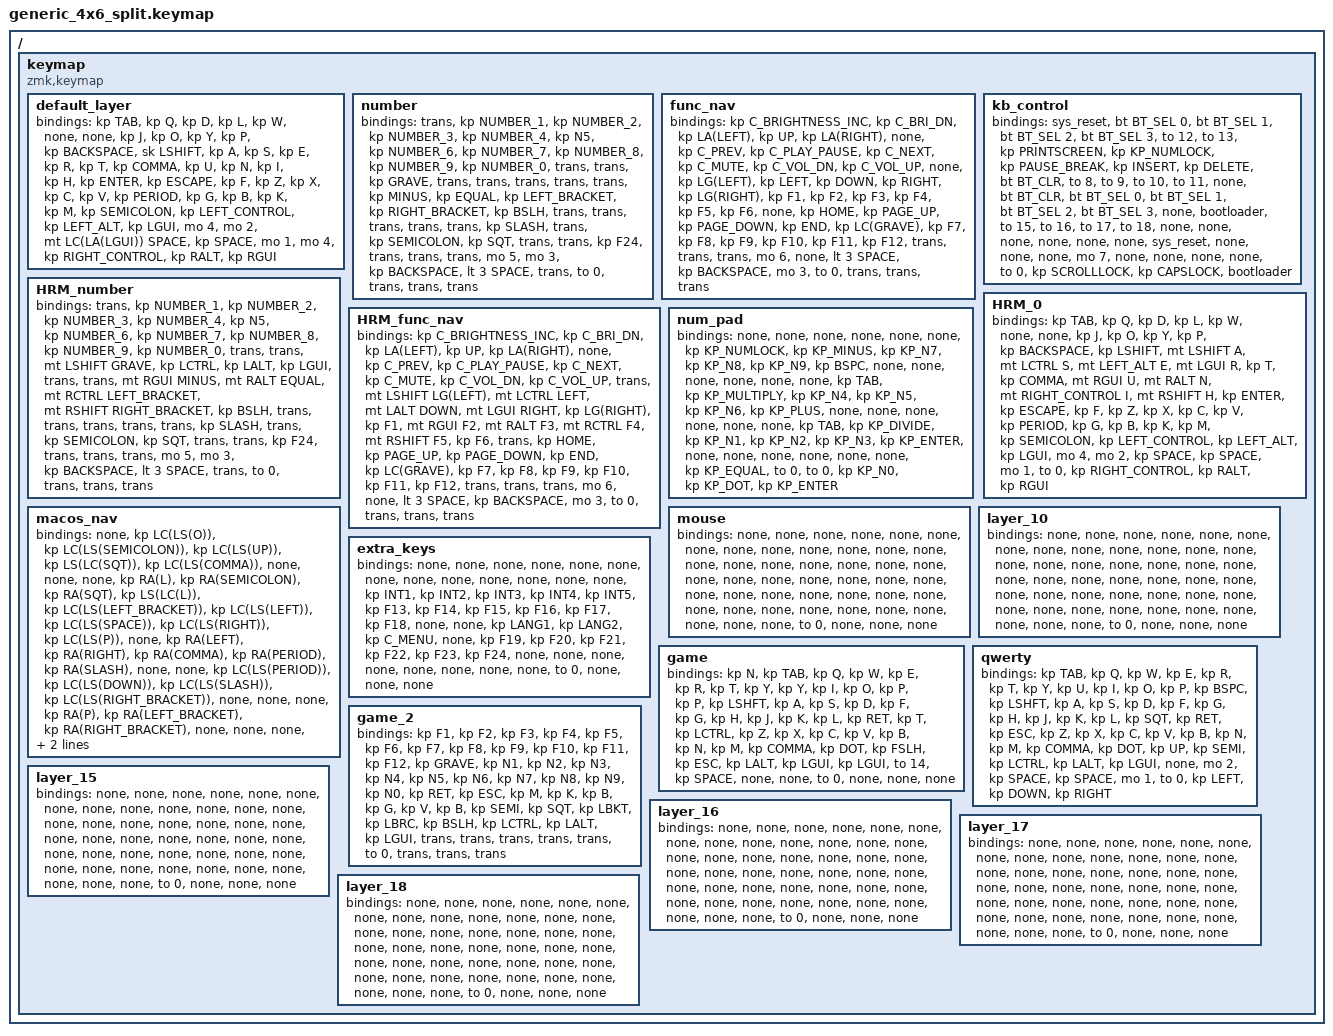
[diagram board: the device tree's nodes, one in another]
#include <behaviors.dtsi>
#include <dt-bindings/zmk/bt.h>
#include <dt-bindings/zmk/keys.h>

/ {
    keymap {
        compatible = "zmk,keymap";

        default_layer {
            bindings = <
&kp TAB  &kp Q  &kp D  &kp L  &kp W  &none  &none  &kp J  &kp O  &kp Y  &kp P  &kp BACKSPACE  &sk LSHIFT  &kp A  &kp S  &kp E  &kp R  &kp T  &kp COMMA  &kp U  &kp N  &kp I  &kp H  &kp ENTER  &kp ESCAPE  &kp F  &kp Z  &kp X  &kp C  &kp V  &kp PERIOD  &kp G  &kp B  &kp K  &kp M  &kp SEMICOLON  &kp LEFT_CONTROL  &kp LEFT_ALT  &kp LGUI  &mo 4  &mo 2  &mt LC(LA(LGUI)) SPACE  &kp SPACE  &mo 1  &mo 4  &kp RIGHT_CONTROL  &kp RALT  &kp RGUI
            >;
        };

        number {
            bindings = <
&trans  &kp NUMBER_1  &kp NUMBER_2  &kp NUMBER_3  &kp NUMBER_4  &kp N5  &kp NUMBER_6  &kp NUMBER_7  &kp NUMBER_8  &kp NUMBER_9  &kp NUMBER_0  &trans  &trans  &kp GRAVE  &trans  &trans  &trans  &trans  &trans  &kp MINUS  &kp EQUAL  &kp LEFT_BRACKET  &kp RIGHT_BRACKET  &kp BSLH  &trans  &trans  &trans  &trans  &trans  &kp SLASH  &trans  &kp SEMICOLON  &kp SQT  &trans  &trans  &kp F24  &trans  &trans  &trans  &mo 5  &mo 3  &kp BACKSPACE  &lt 3 SPACE  &trans  &to 0  &trans  &trans  &trans
            >;
        };

        func_nav {
            bindings = <
&kp C_BRIGHTNESS_INC  &kp C_BRI_DN  &kp LA(LEFT)  &kp UP  &kp LA(RIGHT)  &none  &kp C_PREV  &kp C_PLAY_PAUSE  &kp C_NEXT  &kp C_MUTE  &kp C_VOL_DN  &kp C_VOL_UP  &none  &kp LG(LEFT)  &kp LEFT  &kp DOWN  &kp RIGHT  &kp LG(RIGHT)  &kp F1  &kp F2  &kp F3  &kp F4  &kp F5  &kp F6  &none  &kp HOME  &kp PAGE_UP  &kp PAGE_DOWN  &kp END  &kp LC(GRAVE)  &kp F7  &kp F8  &kp F9  &kp F10  &kp F11  &kp F12  &trans  &trans  &trans  &mo 6  &none  &lt 3 SPACE  &kp BACKSPACE  &mo 3  &to 0  &trans  &trans  &trans
            >;
        };

        kb_control {
            bindings = <
&sys_reset  &bt BT_SEL 0  &bt BT_SEL 1  &bt BT_SEL 2  &bt BT_SEL 3  &to 12  &to 13  &kp PRINTSCREEN  &kp KP_NUMLOCK  &kp PAUSE_BREAK  &kp INSERT  &kp DELETE  &bt BT_CLR  &to 8  &to 9  &to 10  &to 11  &none  &bt BT_CLR  &bt BT_SEL 0  &bt BT_SEL 1  &bt BT_SEL 2  &bt BT_SEL 3  &none  &bootloader  &to 15  &to 16  &to 17  &to 18  &none  &none  &none  &none  &none  &none  &sys_reset  &none  &none  &none  &mo 7  &none  &none  &none  &none  &to 0  &kp SCROLLLOCK  &kp CAPSLOCK  &bootloader
            >;
        };

        HRM_0 {
            bindings = <
&kp TAB  &kp Q  &kp D  &kp L  &kp W  &none  &none  &kp J  &kp O  &kp Y  &kp P  &kp BACKSPACE  &kp LSHIFT  &mt LSHIFT A  &mt LCTRL S  &mt LEFT_ALT E  &mt LGUI R  &kp T  &kp COMMA  &mt RGUI U  &mt RALT N  &mt RIGHT_CONTROL I  &mt RSHIFT H  &kp ENTER  &kp ESCAPE  &kp F  &kp Z  &kp X  &kp C  &kp V  &kp PERIOD  &kp G  &kp B  &kp K  &kp M  &kp SEMICOLON  &kp LEFT_CONTROL  &kp LEFT_ALT  &kp LGUI  &mo 4  &mo 2  &kp SPACE  &kp SPACE  &mo 1  &to 0  &kp RIGHT_CONTROL  &kp RALT  &kp RGUI
            >;
        };

        HRM_number {
            bindings = <
&trans  &kp NUMBER_1  &kp NUMBER_2  &kp NUMBER_3  &kp NUMBER_4  &kp N5  &kp NUMBER_6  &kp NUMBER_7  &kp NUMBER_8  &kp NUMBER_9  &kp NUMBER_0  &trans  &trans  &mt LSHIFT GRAVE  &kp LCTRL  &kp LALT  &kp LGUI  &trans  &trans  &mt RGUI MINUS  &mt RALT EQUAL  &mt RCTRL LEFT_BRACKET  &mt RSHIFT RIGHT_BRACKET  &kp BSLH  &trans  &trans  &trans  &trans  &trans  &kp SLASH  &trans  &kp SEMICOLON  &kp SQT  &trans  &trans  &kp F24  &trans  &trans  &trans  &mo 5  &mo 3  &kp BACKSPACE  &lt 3 SPACE  &trans  &to 0  &trans  &trans  &trans
            >;
        };

        HRM_func_nav {
            bindings = <
&kp C_BRIGHTNESS_INC  &kp C_BRI_DN  &kp LA(LEFT)  &kp UP  &kp LA(RIGHT)  &none  &kp C_PREV  &kp C_PLAY_PAUSE  &kp C_NEXT  &kp C_MUTE  &kp C_VOL_DN  &kp C_VOL_UP  &trans  &mt LSHIFT LG(LEFT)  &mt LCTRL LEFT  &mt LALT DOWN  &mt LGUI RIGHT  &kp LG(RIGHT)  &kp F1  &mt RGUI F2  &mt RALT F3  &mt RCTRL F4  &mt RSHIFT F5  &kp F6  &trans  &kp HOME  &kp PAGE_UP  &kp PAGE_DOWN  &kp END  &kp LC(GRAVE)  &kp F7  &kp F8  &kp F9  &kp F10  &kp F11  &kp F12  &trans  &trans  &trans  &mo 6  &none  &lt 3 SPACE  &kp BACKSPACE  &mo 3  &to 0  &trans  &trans  &trans
            >;
        };

        macos_nav {
            bindings = <
&none  &kp LC(LS(O))  &kp LC(LS(SEMICOLON))  &kp LC(LS(UP))  &kp LS(LC(SQT))  &kp LC(LS(COMMA))  &none  &none  &none  &kp RA(L)  &kp RA(SEMICOLON)  &kp RA(SQT)  &kp LS(LC(L))  &kp LC(LS(LEFT_BRACKET))  &kp LC(LS(LEFT))  &kp LC(LS(SPACE))  &kp LC(LS(RIGHT))  &kp LC(LS(P))  &none  &kp RA(LEFT)  &kp RA(RIGHT)  &kp RA(COMMA)  &kp RA(PERIOD)  &kp RA(SLASH)  &none  &none  &kp LC(LS(PERIOD))  &kp LC(LS(DOWN))  &kp LC(LS(SLASH))  &kp LC(LS(RIGHT_BRACKET))  &none  &none  &none  &kp RA(P)  &kp RA(LEFT_BRACKET)  &kp RA(RIGHT_BRACKET)  &none  &none  &none  &none  &none  &none  &none  &none  &to 0  &none  &none  &none
            >;
        };

        num_pad {
            bindings = <
&none  &none  &none  &none  &none  &none  &kp KP_NUMLOCK  &kp KP_MINUS  &kp KP_N7  &kp KP_N8  &kp KP_N9  &kp BSPC  &none  &none  &none  &none  &none  &none  &kp TAB  &kp KP_MULTIPLY  &kp KP_N4  &kp KP_N5  &kp KP_N6  &kp KP_PLUS  &none  &none  &none  &none  &none  &none  &kp TAB  &kp KP_DIVIDE  &kp KP_N1  &kp KP_N2  &kp KP_N3  &kp KP_ENTER  &none  &none  &none  &none  &none  &none  &kp KP_EQUAL  &to 0  &to 0  &kp KP_N0  &kp KP_DOT  &kp KP_ENTER
            >;
        };

        mouse {
            bindings = <
&none  &none  &none  &none  &none  &none  &none  &none  &none  &none  &none  &none  &none  &none  &none  &none  &none  &none  &none  &none  &none  &none  &none  &none  &none  &none  &none  &none  &none  &none  &none  &none  &none  &none  &none  &none  &none  &none  &none  &none  &none  &none  &none  &none  &to 0  &none  &none  &none
            >;
        };

        layer_10 {
            bindings = <
&none  &none  &none  &none  &none  &none  &none  &none  &none  &none  &none  &none  &none  &none  &none  &none  &none  &none  &none  &none  &none  &none  &none  &none  &none  &none  &none  &none  &none  &none  &none  &none  &none  &none  &none  &none  &none  &none  &none  &none  &none  &none  &none  &none  &to 0  &none  &none  &none
            >;
        };

        extra_keys {
            bindings = <
&none  &none  &none  &none  &none  &none  &none  &none  &none  &none  &none  &none  &none  &kp INT1  &kp INT2  &kp INT3  &kp INT4  &kp INT5  &kp F13  &kp F14  &kp F15  &kp F16  &kp F17  &kp F18  &none  &none  &kp LANG1  &kp LANG2  &kp C_MENU  &none  &kp F19  &kp F20  &kp F21  &kp F22  &kp F23  &kp F24  &none  &none  &none  &none  &none  &none  &none  &none  &to 0  &none  &none  &none
            >;
        };

        game {
            bindings = <
&kp N  &kp TAB  &kp Q  &kp W  &kp E  &kp R  &kp T  &kp Y  &kp Y  &kp I  &kp O  &kp P  &kp P  &kp LSHFT  &kp A  &kp S  &kp D  &kp F  &kp G  &kp H  &kp J  &kp K  &kp L  &kp RET  &kp T  &kp LCTRL  &kp Z  &kp X  &kp C  &kp V  &kp B  &kp N  &kp M  &kp COMMA  &kp DOT  &kp FSLH  &kp ESC  &kp LALT  &kp LGUI  &kp LGUI  &to 14  &kp SPACE  &none  &none  &to 0  &none  &none  &none
            >;
        };

        qwerty {
            bindings = <
&kp TAB  &kp Q  &kp W  &kp E  &kp R  &kp T  &kp Y  &kp U  &kp I  &kp O  &kp P  &kp BSPC  &kp LSHFT  &kp A  &kp S  &kp D  &kp F  &kp G  &kp H  &kp J  &kp K  &kp L  &kp SQT  &kp RET  &kp ESC  &kp Z  &kp X  &kp C  &kp V  &kp B  &kp N  &kp M  &kp COMMA  &kp DOT  &kp UP  &kp SEMI  &kp LCTRL  &kp LALT  &kp LGUI  &none  &mo 2  &kp SPACE  &kp SPACE  &mo 1  &to 0  &kp LEFT  &kp DOWN  &kp RIGHT
            >;
        };

        game_2 {
            bindings = <
&kp F1  &kp F2  &kp F3  &kp F4  &kp F5  &kp F6  &kp F7  &kp F8  &kp F9  &kp F10  &kp F11  &kp F12  &kp GRAVE  &kp N1  &kp N2  &kp N3  &kp N4  &kp N5  &kp N6  &kp N7  &kp N8  &kp N9  &kp N0  &kp RET  &kp ESC  &kp M  &kp K  &kp B  &kp G  &kp V  &kp B  &kp SEMI  &kp SQT  &kp LBKT  &kp LBRC  &kp BSLH  &kp LCTRL  &kp LALT  &kp LGUI  &trans  &trans  &trans  &trans  &trans  &to 0  &trans  &trans  &trans
            >;
        };

        layer_15 {
            bindings = <
&none  &none  &none  &none  &none  &none  &none  &none  &none  &none  &none  &none  &none  &none  &none  &none  &none  &none  &none  &none  &none  &none  &none  &none  &none  &none  &none  &none  &none  &none  &none  &none  &none  &none  &none  &none  &none  &none  &none  &none  &none  &none  &none  &none  &to 0  &none  &none  &none
            >;
        };

        layer_16 {
            bindings = <
&none  &none  &none  &none  &none  &none  &none  &none  &none  &none  &none  &none  &none  &none  &none  &none  &none  &none  &none  &none  &none  &none  &none  &none  &none  &none  &none  &none  &none  &none  &none  &none  &none  &none  &none  &none  &none  &none  &none  &none  &none  &none  &none  &none  &to 0  &none  &none  &none
            >;
        };

        layer_17 {
            bindings = <
&none  &none  &none  &none  &none  &none  &none  &none  &none  &none  &none  &none  &none  &none  &none  &none  &none  &none  &none  &none  &none  &none  &none  &none  &none  &none  &none  &none  &none  &none  &none  &none  &none  &none  &none  &none  &none  &none  &none  &none  &none  &none  &none  &none  &to 0  &none  &none  &none
            >;
        };

        layer_18 {
            bindings = <
&none  &none  &none  &none  &none  &none  &none  &none  &none  &none  &none  &none  &none  &none  &none  &none  &none  &none  &none  &none  &none  &none  &none  &none  &none  &none  &none  &none  &none  &none  &none  &none  &none  &none  &none  &none  &none  &none  &none  &none  &none  &none  &none  &none  &to 0  &none  &none  &none
            >;
        };
    };
};
